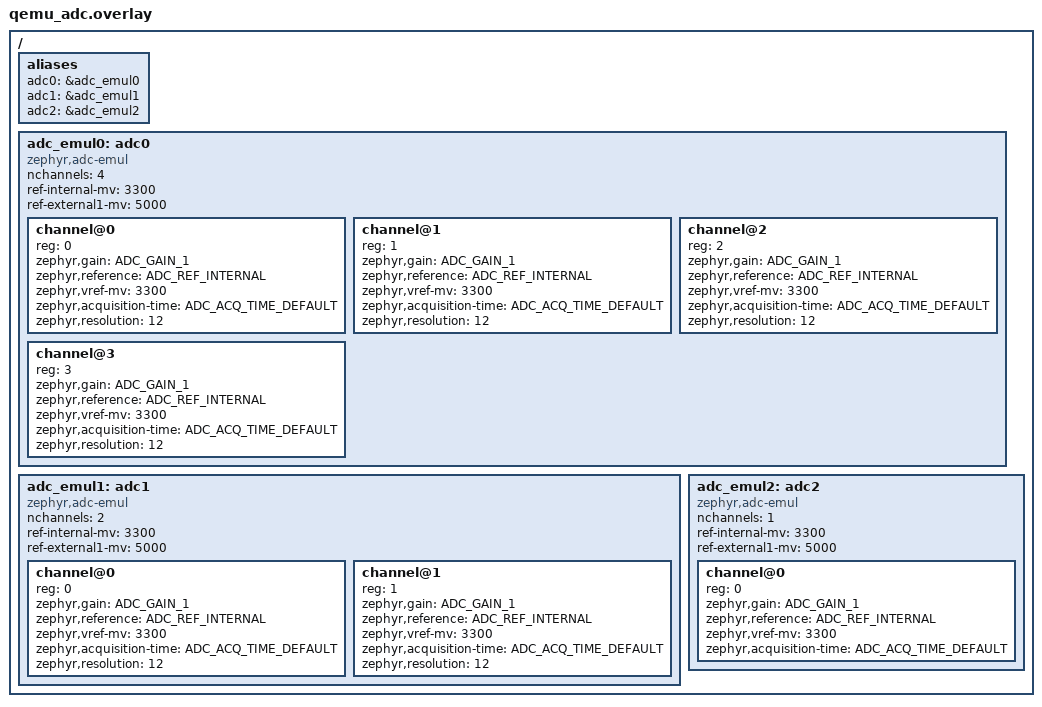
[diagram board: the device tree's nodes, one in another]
/*
 * Two emulated ADCs (four channels then two) for QEMU targets, matching the
 * topology the native_sim overlay builds on top of that board's own adc node,
 * plus a third one whose channel states no resolution, which Initialize()
 * must reject.
 */

#include <zephyr/dt-bindings/adc/adc.h>

/ {
	aliases {
		adc0 = &adc_emul0;
		adc1 = &adc_emul1;
		adc2 = &adc_emul2;
	};

	adc_emul0: adc0 {
		compatible = "zephyr,adc-emul";
		nchannels = <4>;
		ref-internal-mv = <3300>;
		ref-external1-mv = <5000>;
		#io-channel-cells = <1>;
		#address-cells = <1>;
		#size-cells = <0>;
		status = "okay";

		channel@0 {
			reg = <0>;
			zephyr,gain = "ADC_GAIN_1";
			zephyr,reference = "ADC_REF_INTERNAL";
			zephyr,vref-mv = <3300>;
			zephyr,acquisition-time = <ADC_ACQ_TIME_DEFAULT>;
			zephyr,resolution = <12>;
		};

		channel@1 {
			reg = <1>;
			zephyr,gain = "ADC_GAIN_1";
			zephyr,reference = "ADC_REF_INTERNAL";
			zephyr,vref-mv = <3300>;
			zephyr,acquisition-time = <ADC_ACQ_TIME_DEFAULT>;
			zephyr,resolution = <12>;
		};

		channel@2 {
			reg = <2>;
			zephyr,gain = "ADC_GAIN_1";
			zephyr,reference = "ADC_REF_INTERNAL";
			zephyr,vref-mv = <3300>;
			zephyr,acquisition-time = <ADC_ACQ_TIME_DEFAULT>;
			zephyr,resolution = <12>;
		};

		channel@3 {
			reg = <3>;
			zephyr,gain = "ADC_GAIN_1";
			zephyr,reference = "ADC_REF_INTERNAL";
			zephyr,vref-mv = <3300>;
			zephyr,acquisition-time = <ADC_ACQ_TIME_DEFAULT>;
			zephyr,resolution = <12>;
		};
	};

	adc_emul1: adc1 {
		compatible = "zephyr,adc-emul";
		nchannels = <2>;
		ref-internal-mv = <3300>;
		ref-external1-mv = <5000>;
		#io-channel-cells = <1>;
		#address-cells = <1>;
		#size-cells = <0>;
		status = "okay";

		channel@0 {
			reg = <0>;
			zephyr,gain = "ADC_GAIN_1";
			zephyr,reference = "ADC_REF_INTERNAL";
			zephyr,vref-mv = <3300>;
			zephyr,acquisition-time = <ADC_ACQ_TIME_DEFAULT>;
			zephyr,resolution = <12>;
		};

		channel@1 {
			reg = <1>;
			zephyr,gain = "ADC_GAIN_1";
			zephyr,reference = "ADC_REF_INTERNAL";
			zephyr,vref-mv = <3300>;
			zephyr,acquisition-time = <ADC_ACQ_TIME_DEFAULT>;
			zephyr,resolution = <12>;
		};
	};

	adc_emul2: adc2 {
		compatible = "zephyr,adc-emul";
		nchannels = <1>;
		ref-internal-mv = <3300>;
		ref-external1-mv = <5000>;
		#io-channel-cells = <1>;
		#address-cells = <1>;
		#size-cells = <0>;
		status = "okay";

		channel@0 {
			reg = <0>;
			zephyr,gain = "ADC_GAIN_1";
			zephyr,reference = "ADC_REF_INTERNAL";
			zephyr,vref-mv = <3300>;
			zephyr,acquisition-time = <ADC_ACQ_TIME_DEFAULT>;
		};
	};
};
